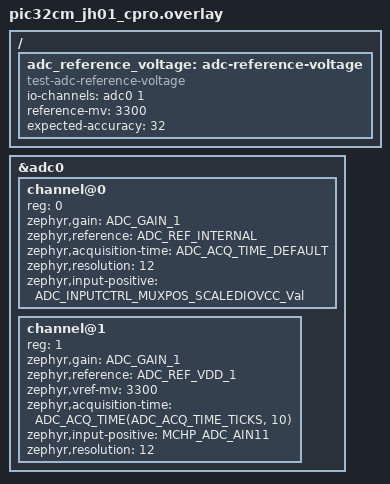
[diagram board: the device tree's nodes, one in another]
/*
 * Copyright (c) 2026 Microchip Technology Inc.
 *
 * SPDX-License-Identifier: Apache-2.0
 */

#define ADC_INPUTCTRL_MUXPOS_SCALEDIOVCC_Val 0x1BU

&adc0 {
	#address-cells = <1>;
	#size-cells = <0>;
	status = "okay";

	channel@0 {
		reg = <0>;
		zephyr,gain = "ADC_GAIN_1";
		zephyr,reference = "ADC_REF_INTERNAL";
		zephyr,acquisition-time = <ADC_ACQ_TIME_DEFAULT>;
		zephyr,resolution = <12>;
		zephyr,input-positive = <ADC_INPUTCTRL_MUXPOS_SCALEDIOVCC_Val>;
	};

	channel@1 {
		reg = <1>;
		zephyr,gain = "ADC_GAIN_1";
		zephyr,reference = "ADC_REF_VDD_1";
		zephyr,vref-mv = <3300>;
		zephyr,acquisition-time = <ADC_ACQ_TIME(ADC_ACQ_TIME_TICKS, 10)>;
		zephyr,input-positive = <MCHP_ADC_AIN11>;
		zephyr,resolution = <12>;
	};
};

/ {
	adc_reference_voltage: adc-reference-voltage {
		compatible = "test-adc-reference-voltage";
		io-channels = <&adc0 1>;
		reference-mv = <3300>;
		expected-accuracy = <32>;
	};
};
